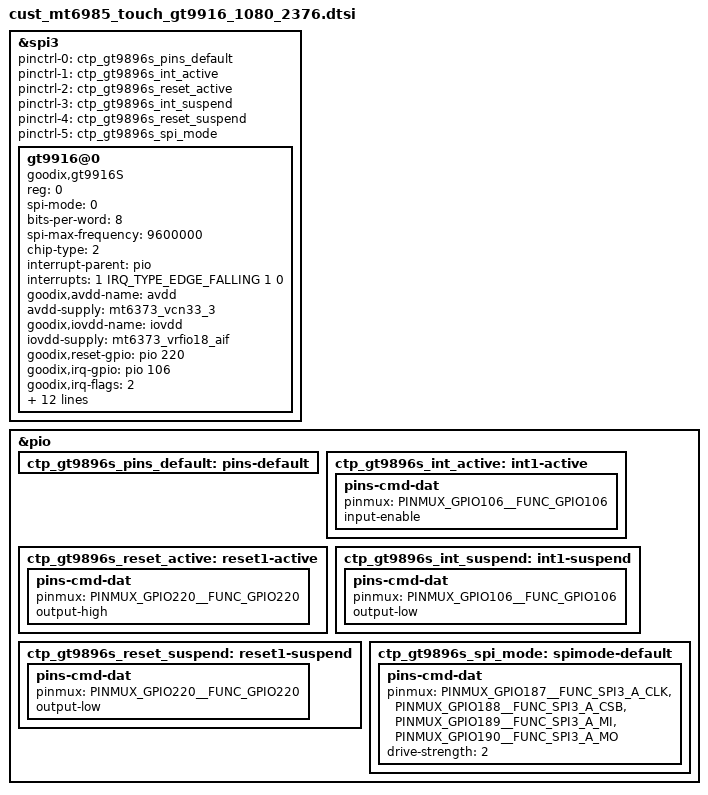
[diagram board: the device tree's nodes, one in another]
// SPDX-License-Identifier: (GPL-2.0 OR MIT)
/*
 * Copyright (C) 2022 MediaTek Inc.
 */

/* TOUCH start */
&spi3 {
	status = "okay";
	#address-cells = <1>;
	#size-cells = <0>;
	pinctrl-names = "default", "gt9896s_int_active",
		"gt9896s_reset_active", "gt9896s_int_suspend",
		"gt9896s_reset_suspend", "gt9896s_spi_mode";
	pinctrl-0 = <&ctp_gt9896s_pins_default>;
	pinctrl-1 = <&ctp_gt9896s_int_active>;
	pinctrl-2 = <&ctp_gt9896s_reset_active>;
	pinctrl-3 = <&ctp_gt9896s_int_suspend>;
	pinctrl-4 = <&ctp_gt9896s_reset_suspend>;
	pinctrl-5 = <&ctp_gt9896s_spi_mode>;

	gt9916@0 {
		compatible = "goodix,gt9916S", "goodix,brl-d";
		status = "okay";
		reg = <0>; //Same as CS ID

		spi-mode = <0>;
		bits-per-word = <8>;
		spi-max-frequency = <9600000>;
		chip-type = <2>;
		interrupt-parent = <&pio>;
		interrupts = <1 IRQ_TYPE_EDGE_FALLING 1 0>;
		goodix,avdd-name = "avdd";
		avdd-supply = <&mt6373_vcn33_3>;	/*3V PMIC*/
		goodix,iovdd-name = "iovdd";
		iovdd-supply = <&mt6373_vrfio18_aif>; //1V8 connect INT, need power enable
		goodix,reset-gpio = <&pio 220 0x00>;
		goodix,irq-gpio = <&pio 106 0x00>;
		goodix,irq-flags = <2>; /* 1:rising, 2:falling;*/
		gt9895,power-voltage = <3000000>;
		gt9895,firmware-name = "gt9916_firmware_6985v21.bin";
		gt9895,config-name = "gt9916_cfg_6985v21.bin";

		/*goodix,panel-max-id = <10>;*/
		goodix,panel-max-x = <12600>;
		goodix,panel-max-y = <28000>;
		goodix,panel-max-w = <256>;
		goodix,panel-max-p = <256>;
		goodix,panel-key-map = <158 172 217>; /*BACK,HOMEPAGE,SEARCH*/
		goodix,power-on-delay-us = <100000>; /*300ms*/
		goodix,power-off-delay-us = <10000>;
		/*goodix,swap-axis;*/
		goodix,pen-enable;
	};
};

&pio {
	ctp_gt9896s_pins_default: pins-default {
	};
	ctp_gt9896s_int_active: int1-active {
		pins-cmd-dat {
			pinmux = <PINMUX_GPIO106__FUNC_GPIO106>;
			input-enable;
		};
	};
	ctp_gt9896s_reset_active: reset1-active {
		pins-cmd-dat {
			pinmux = <PINMUX_GPIO220__FUNC_GPIO220>;
			output-high;
		};
	};
	ctp_gt9896s_int_suspend: int1-suspend {
		pins-cmd-dat {
			pinmux = <PINMUX_GPIO106__FUNC_GPIO106>;
			output-low;
		};
	};
	ctp_gt9896s_reset_suspend: reset1-suspend {
		pins-cmd-dat {
			pinmux = <PINMUX_GPIO220__FUNC_GPIO220>;
			output-low;
		};
	};
	ctp_gt9896s_spi_mode: spimode-default {
		pins-cmd-dat {
			pinmux = <PINMUX_GPIO187__FUNC_SPI3_A_CLK>,
				<PINMUX_GPIO188__FUNC_SPI3_A_CSB>,
				<PINMUX_GPIO189__FUNC_SPI3_A_MI>,
				<PINMUX_GPIO190__FUNC_SPI3_A_MO>;
			drive-strength = <2>;
		};
	};
};
